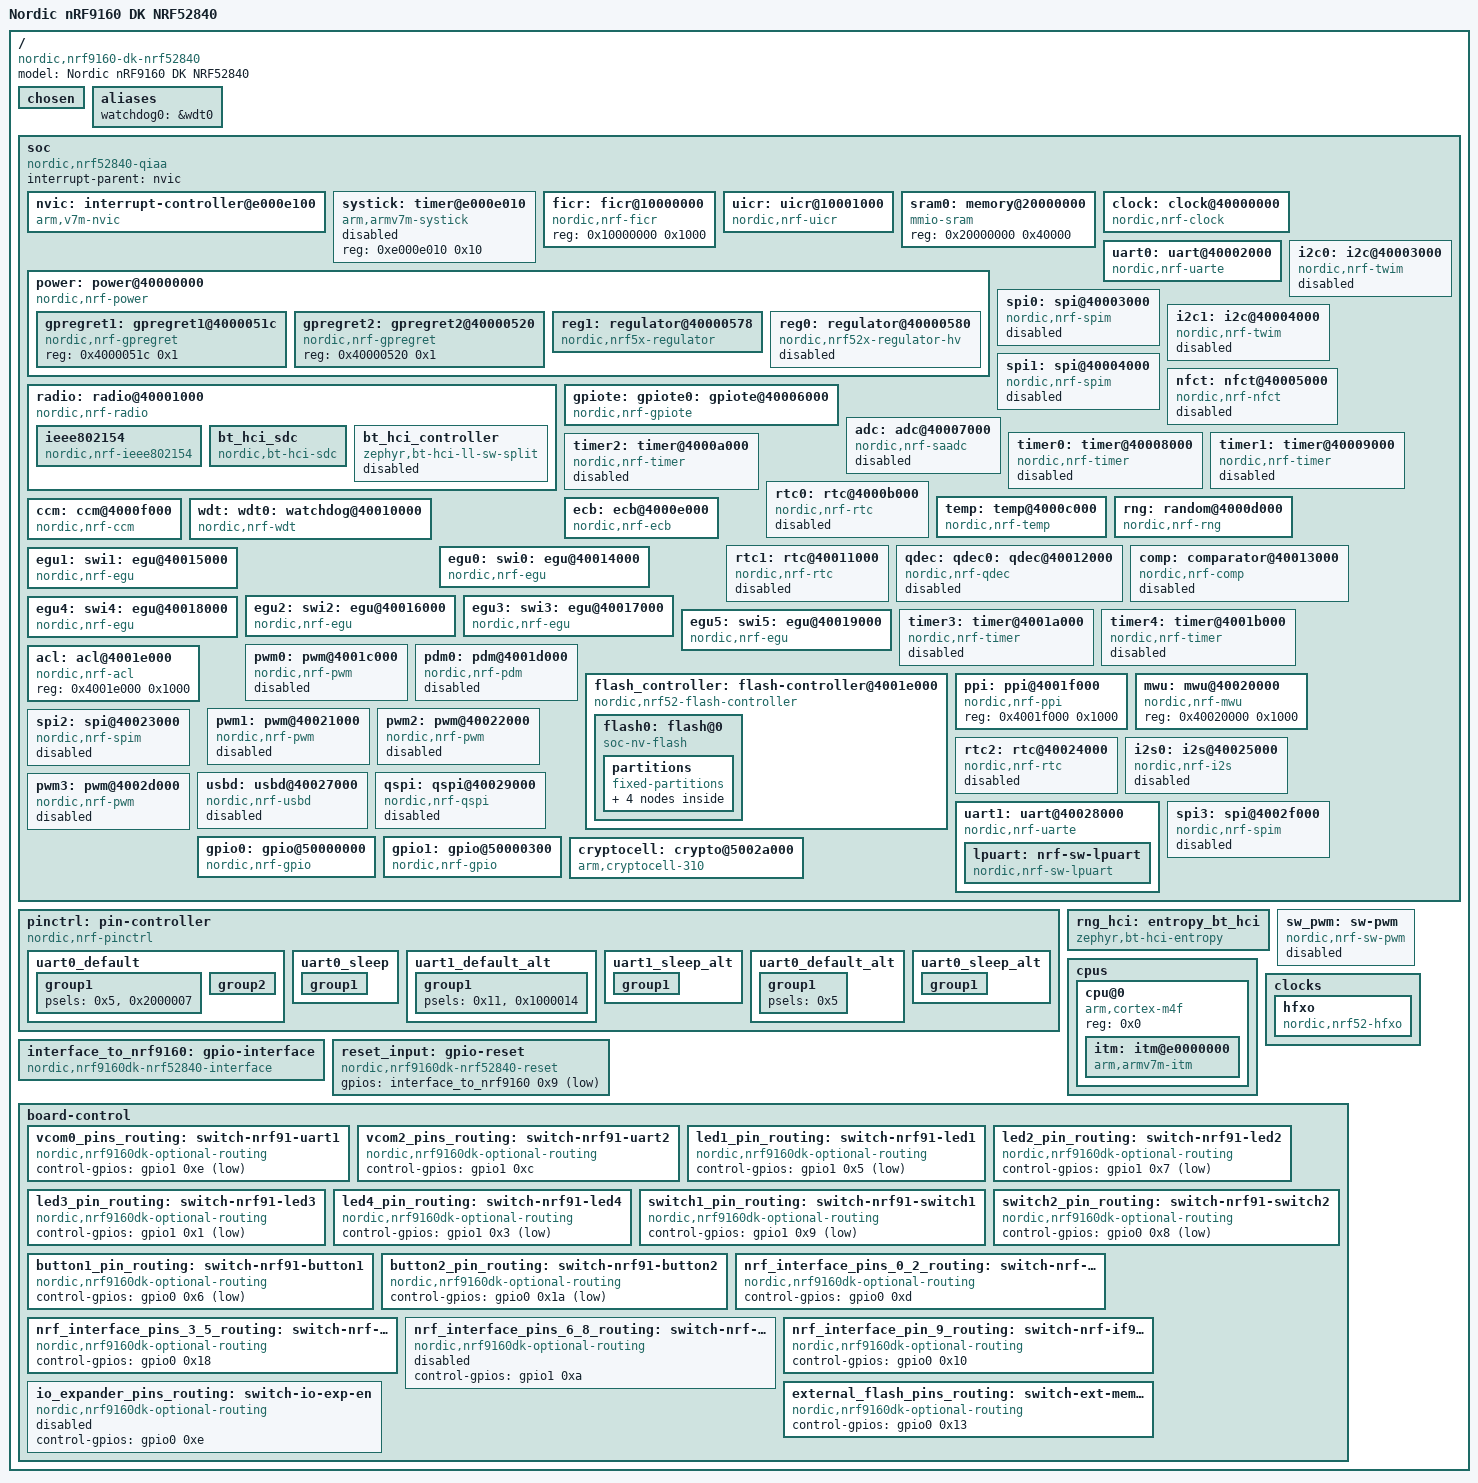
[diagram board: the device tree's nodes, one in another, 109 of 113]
/dts-v1/;

/* node '/' defined in zephyr\dts\common\skeleton.dtsi:9 */
/ {
	#address-cells = < 0x1 >;                  /* in zephyr\dts\common\skeleton.dtsi:10 */
	#size-cells = < 0x1 >;                     /* in zephyr\dts\common\skeleton.dtsi:11 */
	model = "Nordic nRF9160 DK NRF52840";      /* in zephyr\boards\nordic\nrf9160dk\nrf9160dk_nrf52840.dts:14 */
	compatible = "nordic,nrf9160-dk-nrf52840"; /* in zephyr\boards\nordic\nrf9160dk\nrf9160dk_nrf52840.dts:15 */

	/* node '/chosen' defined in zephyr\dts\common\skeleton.dtsi:12 */
	chosen {
		zephyr,bt-hci = &bt_hci_sdc;                 /* in zephyr\dts\arm\nordic\nrf52840.dtsi:10 */
		zephyr,entropy = &cryptocell;                /* in zephyr\dts\arm\nordic\nrf52840.dtsi:11 */
		zephyr,flash-controller = &flash_controller; /* in zephyr\dts\arm\nordic\nrf52840.dtsi:12 */
		zephyr,sram = &sram0;                        /* in zephyr\dts\vendor\nordic\nrf52840_partition.dtsi:9 */
		zephyr,flash = &flash0;                      /* in zephyr\dts\vendor\nordic\nrf52840_partition.dtsi:10 */
		zephyr,code-partition = &slot0_partition;    /* in zephyr\dts\vendor\nordic\nrf52840_partition.dtsi:11 */
		zephyr,console = &uart0;                     /* in zephyr\boards\nordic\nrf9160dk\nrf9160dk_nrf52840.dts:18 */
		zephyr,shell-uart = &uart0;                  /* in zephyr\boards\nordic\nrf9160dk\nrf9160dk_nrf52840.dts:19 */
		zephyr,uart-mcumgr = &uart0;                 /* in zephyr\boards\nordic\nrf9160dk\nrf9160dk_nrf52840.dts:20 */
		zephyr,bt-mon-uart = &uart0;                 /* in zephyr\boards\nordic\nrf9160dk\nrf9160dk_nrf52840.dts:21 */
		zephyr,ieee802154 = &ieee802154;             /* in zephyr\boards\nordic\nrf9160dk\nrf9160dk_nrf52840.dts:22 */
		zephyr,bt-c2h-uart = &lpuart;                /* in pouch-gateway\controller\boards\nrf9160dk_nrf52840.overlay:53 */
	};

	/* node '/aliases' defined in zephyr\dts\common\skeleton.dtsi:13 */
	aliases {
		watchdog0 = &wdt0; /* in zephyr\boards\nordic\nrf9160dk\nrf9160dk_nrf52840.dts:138 */
	};

	/* node '/soc' defined in zephyr\dts\arm\armv7-m.dtsi:6 */
	soc {
		#address-cells = < 0x1 >;            /* in zephyr\dts\arm\armv7-m.dtsi:7 */
		#size-cells = < 0x1 >;               /* in zephyr\dts\arm\armv7-m.dtsi:8 */
		compatible = "nordic,nrf52840-qiaa",
		             "nordic,nrf52840",
		             "nordic,nrf52",
		             "simple-bus";           /* in zephyr\dts\arm\nordic\nrf52840_qiaa.dtsi:29 */
		interrupt-parent = < &nvic >;        /* in zephyr\dts\arm\armv7-m.dtsi:10 */
		ranges;                              /* in zephyr\dts\arm\armv7-m.dtsi:11 */

		/* node '/soc/interrupt-controller@e000e100' defined in zephyr\dts\arm\armv7-m.dtsi:13 */
		nvic: interrupt-controller@e000e100 {
			#address-cells = < 0x1 >;            /* in zephyr\dts\arm\armv7-m.dtsi:14 */
			compatible = "arm,v7m-nvic";         /* in zephyr\dts\arm\armv7-m.dtsi:15 */
			reg = < 0xe000e100 0xc00 >;          /* in zephyr\dts\arm\armv7-m.dtsi:16 */
			interrupt-controller;                /* in zephyr\dts\arm\armv7-m.dtsi:17 */
			#interrupt-cells = < 0x2 >;          /* in zephyr\dts\arm\armv7-m.dtsi:18 */
			arm,num-irq-priority-bits = < 0x3 >; /* in zephyr\dts\arm\nordic\nrf52840.dtsi:582 */
			phandle = < 0x1 >;                   /* in zephyr\dts\arm\armv7-m.dtsi:10 */
		};

		/* node '/soc/timer@e000e010' defined in zephyr\dts\arm\armv7-m.dtsi:21 */
		systick: timer@e000e010 {
			compatible = "arm,armv7m-systick"; /* in zephyr\dts\arm\armv7-m.dtsi:22 */
			reg = < 0xe000e010 0x10 >;         /* in zephyr\dts\arm\armv7-m.dtsi:23 */
			status = "disabled";               /* in zephyr\dts\arm\nordic\nrf52840.dtsi:587 */
		};

		/* node '/soc/ficr@10000000' defined in zephyr\dts\arm\nordic\nrf52840.dtsi:44 */
		ficr: ficr@10000000 {
			compatible = "nordic,nrf-ficr"; /* in zephyr\dts\arm\nordic\nrf52840.dtsi:45 */
			reg = < 0x10000000 0x1000 >;    /* in zephyr\dts\arm\nordic\nrf52840.dtsi:46 */
			#nordic,ficr-cells = < 0x1 >;   /* in zephyr\dts\arm\nordic\nrf52840.dtsi:47 */
			status = "okay";                /* in zephyr\dts\arm\nordic\nrf52840.dtsi:48 */
		};

		/* node '/soc/uicr@10001000' defined in zephyr\dts\arm\nordic\nrf52840.dtsi:51 */
		uicr: uicr@10001000 {
			compatible = "nordic,nrf-uicr"; /* in zephyr\dts\arm\nordic\nrf52840.dtsi:52 */
			reg = < 0x10001000 0x1000 >;    /* in zephyr\dts\arm\nordic\nrf52840.dtsi:53 */
			status = "okay";                /* in zephyr\dts\arm\nordic\nrf52840.dtsi:54 */
			gpio-as-nreset;                 /* in zephyr\boards\nordic\nrf9160dk\nrf9160dk_nrf52840.dts:147 */
		};

		/* node '/soc/memory@20000000' defined in zephyr\dts\arm\nordic\nrf52840.dtsi:57 */
		sram0: memory@20000000 {
			compatible = "mmio-sram";     /* in zephyr\dts\arm\nordic\nrf52840.dtsi:58 */
			reg = < 0x20000000 0x40000 >; /* in zephyr\dts\arm\nordic\nrf52840_qiaa.dtsi:15 */
		};

		/* node '/soc/clock@40000000' defined in zephyr\dts\arm\nordic\nrf52840.dtsi:61 */
		clock: clock@40000000 {
			compatible = "nordic,nrf-clock"; /* in zephyr\dts\arm\nordic\nrf52840.dtsi:62 */
			reg = < 0x40000000 0x1000 >;     /* in zephyr\dts\arm\nordic\nrf52840.dtsi:63 */
			interrupts = < 0x0 0x1 >;        /* in zephyr\dts\arm\nordic\nrf52840.dtsi:64 */
			status = "okay";                 /* in zephyr\dts\arm\nordic\nrf52840.dtsi:65 */
		};

		/* node '/soc/power@40000000' defined in zephyr\dts\arm\nordic\nrf52840.dtsi:68 */
		power: power@40000000 {
			compatible = "nordic,nrf-power"; /* in zephyr\dts\arm\nordic\nrf52840.dtsi:69 */
			reg = < 0x40000000 0x1000 >;     /* in zephyr\dts\arm\nordic\nrf52840.dtsi:70 */
			interrupts = < 0x0 0x1 >;        /* in zephyr\dts\arm\nordic\nrf52840.dtsi:71 */
			status = "okay";                 /* in zephyr\dts\arm\nordic\nrf52840.dtsi:72 */
			#address-cells = < 0x1 >;        /* in zephyr\dts\arm\nordic\nrf52840.dtsi:73 */
			#size-cells = < 0x1 >;           /* in zephyr\dts\arm\nordic\nrf52840.dtsi:74 */

			/* node '/soc/power@40000000/gpregret1@4000051c' defined in zephyr\dts\arm\nordic\nrf52840.dtsi:76 */
			gpregret1: gpregret1@4000051c {
				#address-cells = < 0x1 >;           /* in zephyr\dts\arm\nordic\nrf52840.dtsi:77 */
				#size-cells = < 0x1 >;              /* in zephyr\dts\arm\nordic\nrf52840.dtsi:78 */
				compatible = "nordic,nrf-gpregret"; /* in zephyr\dts\arm\nordic\nrf52840.dtsi:79 */
				reg = < 0x4000051c 0x1 >;           /* in zephyr\dts\arm\nordic\nrf52840.dtsi:80 */
				status = "okay";                    /* in zephyr\dts\arm\nordic\nrf52840.dtsi:81 */
			};

			/* node '/soc/power@40000000/gpregret2@40000520' defined in zephyr\dts\arm\nordic\nrf52840.dtsi:84 */
			gpregret2: gpregret2@40000520 {
				#address-cells = < 0x1 >;           /* in zephyr\dts\arm\nordic\nrf52840.dtsi:85 */
				#size-cells = < 0x1 >;              /* in zephyr\dts\arm\nordic\nrf52840.dtsi:86 */
				compatible = "nordic,nrf-gpregret"; /* in zephyr\dts\arm\nordic\nrf52840.dtsi:87 */
				reg = < 0x40000520 0x1 >;           /* in zephyr\dts\arm\nordic\nrf52840.dtsi:88 */
				status = "okay";                    /* in zephyr\dts\arm\nordic\nrf52840.dtsi:89 */
			};

			/* node '/soc/power@40000000/regulator@40000578' defined in zephyr\dts\arm\nordic\nrf52840.dtsi:92 */
			reg1: regulator@40000578 {
				compatible = "nordic,nrf5x-regulator"; /* in zephyr\dts\arm\nordic\nrf52840.dtsi:93 */
				reg = < 0x40000578 0x1 >;              /* in zephyr\dts\arm\nordic\nrf52840.dtsi:94 */
				regulator-name = "REG1";               /* in zephyr\dts\arm\nordic\nrf52840.dtsi:95 */
				regulator-initial-mode = < 0x1 >;      /* in zephyr\boards\nordic\nrf9160dk\nrf9160dk_nrf52840.dts:143 */
			};

			/* node '/soc/power@40000000/regulator@40000580' defined in zephyr\dts\arm\nordic\nrf52840_qiaa.dtsi:19 */
			reg0: regulator@40000580 {
				compatible = "nordic,nrf52x-regulator-hv"; /* in zephyr\dts\arm\nordic\nrf52840_qiaa.dtsi:20 */
				reg = < 0x40000580 0x1 >;                  /* in zephyr\dts\arm\nordic\nrf52840_qiaa.dtsi:21 */
				regulator-name = "REG0";                   /* in zephyr\dts\arm\nordic\nrf52840_qiaa.dtsi:22 */
				status = "disabled";                       /* in zephyr\dts\arm\nordic\nrf52840_qiaa.dtsi:23 */
			};
		};

		/* node '/soc/radio@40001000' defined in zephyr\dts\arm\nordic\nrf52840.dtsi:100 */
		radio: radio@40001000 {
			compatible = "nordic,nrf-radio"; /* in zephyr\dts\arm\nordic\nrf52840.dtsi:101 */
			reg = < 0x40001000 0x1000 >;     /* in zephyr\dts\arm\nordic\nrf52840.dtsi:102 */
			interrupts = < 0x1 0x1 >;        /* in zephyr\dts\arm\nordic\nrf52840.dtsi:103 */
			status = "okay";                 /* in zephyr\dts\arm\nordic\nrf52840.dtsi:104 */
			ieee802154-supported;            /* in zephyr\dts\arm\nordic\nrf52840.dtsi:105 */
			ble-2mbps-supported;             /* in zephyr\dts\arm\nordic\nrf52840.dtsi:106 */
			ble-coded-phy-supported;         /* in zephyr\dts\arm\nordic\nrf52840.dtsi:107 */
			tx-high-power-supported;         /* in zephyr\dts\arm\nordic\nrf52840.dtsi:108 */

			/* node '/soc/radio@40001000/ieee802154' defined in zephyr\dts\arm\nordic\nrf52840.dtsi:110 */
			ieee802154: ieee802154 {
				compatible = "nordic,nrf-ieee802154"; /* in zephyr\dts\arm\nordic\nrf52840.dtsi:111 */
				status = "okay";                      /* in zephyr\boards\nordic\nrf9160dk\nrf9160dk_nrf52840.dts:176 */
			};

			/* node '/soc/radio@40001000/bt_hci_sdc' defined in zephyr\dts\arm\nordic\nrf52840.dtsi:115 */
			bt_hci_sdc: bt_hci_sdc {
				compatible = "nordic,bt-hci-sdc"; /* in zephyr\dts\arm\nordic\nrf52840.dtsi:116 */
				status = "okay";                  /* in zephyr\dts\arm\nordic\nrf52840.dtsi:117 */
			};

			/* node '/soc/radio@40001000/bt_hci_controller' defined in zephyr\dts\arm\nordic\nrf52840.dtsi:119 */
			bt_hci_controller: bt_hci_controller {
				compatible = "zephyr,bt-hci-ll-sw-split"; /* in zephyr\dts\arm\nordic\nrf52840.dtsi:120 */
				status = "disabled";                      /* in zephyr\dts\arm\nordic\nrf52840.dtsi:121 */
			};
		};

		/* node '/soc/uart@40002000' defined in zephyr\dts\arm\nordic\nrf52840.dtsi:125 */
		uart0: uart@40002000 {
			compatible = "nordic,nrf-uarte";    /* in zephyr\boards\nordic\nrf9160dk\nrf9160dk_nrf52840.dts:167 */
			reg = < 0x40002000 0x1000 >;        /* in zephyr\dts\arm\nordic\nrf52840.dtsi:129 */
			interrupts = < 0x2 0x1 >;           /* in zephyr\dts\arm\nordic\nrf52840.dtsi:130 */
			status = "okay";                    /* in zephyr\boards\nordic\nrf9160dk\nrf9160dk_nrf52840.dts:169 */
			current-speed = < 0x1c200 >;        /* in zephyr\boards\nordic\nrf9160dk\nrf9160dk_nrf52840.dts:168 */
			pinctrl-0 = < &uart0_default_alt >; /* in pouch-gateway\controller\boards\nrf9160dk_nrf52840.overlay:63 */
			pinctrl-1 = < &uart0_sleep_alt >;   /* in pouch-gateway\controller\boards\nrf9160dk_nrf52840.overlay:64 */
			pinctrl-names = "default",
			                "sleep";            /* in pouch-gateway\controller\boards\nrf9160dk_nrf52840.overlay:65 */
			disable-rx;                         /* in pouch-gateway\controller\boards\nrf9160dk_nrf52840.overlay:66 */
		};

		/* node '/soc/i2c@40003000' defined in zephyr\dts\arm\nordic\nrf52840.dtsi:134 */
		i2c0: i2c@40003000 {
			compatible = "nordic,nrf-twim"; /* in zephyr\dts\arm\nordic\nrf52840.dtsi:142 */
			#address-cells = < 0x1 >;       /* in zephyr\dts\arm\nordic\nrf52840.dtsi:143 */
			#size-cells = < 0x0 >;          /* in zephyr\dts\arm\nordic\nrf52840.dtsi:144 */
			reg = < 0x40003000 0x1000 >;    /* in zephyr\dts\arm\nordic\nrf52840.dtsi:145 */
			interrupts = < 0x3 0x1 >;       /* in zephyr\dts\arm\nordic\nrf52840.dtsi:146 */
			easydma-maxcnt-bits = < 0x10 >; /* in zephyr\dts\arm\nordic\nrf52840.dtsi:147 */
			status = "disabled";            /* in zephyr\dts\arm\nordic\nrf52840.dtsi:148 */
			zephyr,pm-device-runtime-auto;  /* in zephyr\dts\arm\nordic\nrf52840.dtsi:149 */
		};

		/* node '/soc/spi@40003000' defined in zephyr\dts\arm\nordic\nrf52840.dtsi:152 */
		spi0: spi@40003000 {
			compatible = "nordic,nrf-spim"; /* in zephyr\dts\arm\nordic\nrf52840.dtsi:160 */
			#address-cells = < 0x1 >;       /* in zephyr\dts\arm\nordic\nrf52840.dtsi:161 */
			#size-cells = < 0x0 >;          /* in zephyr\dts\arm\nordic\nrf52840.dtsi:162 */
			reg = < 0x40003000 0x1000 >;    /* in zephyr\dts\arm\nordic\nrf52840.dtsi:163 */
			interrupts = < 0x3 0x1 >;       /* in zephyr\dts\arm\nordic\nrf52840.dtsi:164 */
			max-frequency = < 0x7a1200 >;   /* in zephyr\dts\arm\nordic\nrf52840.dtsi:165 */
			easydma-maxcnt-bits = < 0x10 >; /* in zephyr\dts\arm\nordic\nrf52840.dtsi:166 */
			status = "disabled";            /* in zephyr\dts\arm\nordic\nrf52840.dtsi:167 */
		};

		/* node '/soc/i2c@40004000' defined in zephyr\dts\arm\nordic\nrf52840.dtsi:170 */
		i2c1: i2c@40004000 {
			compatible = "nordic,nrf-twim"; /* in zephyr\dts\arm\nordic\nrf52840.dtsi:178 */
			#address-cells = < 0x1 >;       /* in zephyr\dts\arm\nordic\nrf52840.dtsi:179 */
			#size-cells = < 0x0 >;          /* in zephyr\dts\arm\nordic\nrf52840.dtsi:180 */
			reg = < 0x40004000 0x1000 >;    /* in zephyr\dts\arm\nordic\nrf52840.dtsi:181 */
			interrupts = < 0x4 0x1 >;       /* in zephyr\dts\arm\nordic\nrf52840.dtsi:182 */
			easydma-maxcnt-bits = < 0x10 >; /* in zephyr\dts\arm\nordic\nrf52840.dtsi:183 */
			status = "disabled";            /* in zephyr\dts\arm\nordic\nrf52840.dtsi:184 */
			zephyr,pm-device-runtime-auto;  /* in zephyr\dts\arm\nordic\nrf52840.dtsi:185 */
		};

		/* node '/soc/spi@40004000' defined in zephyr\dts\arm\nordic\nrf52840.dtsi:188 */
		spi1: spi@40004000 {
			compatible = "nordic,nrf-spim"; /* in zephyr\dts\arm\nordic\nrf52840.dtsi:196 */
			#address-cells = < 0x1 >;       /* in zephyr\dts\arm\nordic\nrf52840.dtsi:197 */
			#size-cells = < 0x0 >;          /* in zephyr\dts\arm\nordic\nrf52840.dtsi:198 */
			reg = < 0x40004000 0x1000 >;    /* in zephyr\dts\arm\nordic\nrf52840.dtsi:199 */
			interrupts = < 0x4 0x1 >;       /* in zephyr\dts\arm\nordic\nrf52840.dtsi:200 */
			max-frequency = < 0x7a1200 >;   /* in zephyr\dts\arm\nordic\nrf52840.dtsi:201 */
			easydma-maxcnt-bits = < 0x10 >; /* in zephyr\dts\arm\nordic\nrf52840.dtsi:202 */
			status = "disabled";            /* in zephyr\dts\arm\nordic\nrf52840.dtsi:203 */
		};

		/* node '/soc/nfct@40005000' defined in zephyr\dts\arm\nordic\nrf52840.dtsi:206 */
		nfct: nfct@40005000 {
			compatible = "nordic,nrf-nfct"; /* in zephyr\dts\arm\nordic\nrf52840.dtsi:207 */
			reg = < 0x40005000 0x1000 >;    /* in zephyr\dts\arm\nordic\nrf52840.dtsi:208 */
			interrupts = < 0x5 0x1 >;       /* in zephyr\dts\arm\nordic\nrf52840.dtsi:209 */
			status = "disabled";            /* in zephyr\dts\arm\nordic\nrf52840.dtsi:210 */
		};

		/* node '/soc/gpiote@40006000' defined in zephyr\dts\arm\nordic\nrf52840.dtsi:213 */
		gpiote: gpiote0: gpiote@40006000 {
			compatible = "nordic,nrf-gpiote"; /* in zephyr\dts\arm\nordic\nrf52840.dtsi:214 */
			reg = < 0x40006000 0x1000 >;      /* in zephyr\dts\arm\nordic\nrf52840.dtsi:215 */
			interrupts = < 0x6 0x1 >;         /* in pouch-gateway\controller\boards\nrf9160dk_nrf52840.overlay:58 */
			status = "okay";                  /* in zephyr\boards\nordic\nrf9160dk\nrf9160dk_nrf52840.dts:151 */
			instance = < 0x0 >;               /* in zephyr\dts\arm\nordic\nrf52840.dtsi:218 */
			phandle = < 0x6 >;                /* in zephyr\dts\arm\nordic\nrf52840.dtsi:556 */
		};

		/* node '/soc/adc@40007000' defined in zephyr\dts\arm\nordic\nrf52840.dtsi:221 */
		adc: adc@40007000 {
			compatible = "nordic,nrf-saadc"; /* in zephyr\dts\arm\nordic\nrf52840.dtsi:222 */
			reg = < 0x40007000 0x1000 >;     /* in zephyr\dts\arm\nordic\nrf52840.dtsi:223 */
			interrupts = < 0x7 0x1 >;        /* in zephyr\dts\arm\nordic\nrf52840.dtsi:224 */
			status = "disabled";             /* in zephyr\dts\arm\nordic\nrf52840.dtsi:225 */
			#io-channel-cells = < 0x1 >;     /* in zephyr\dts\arm\nordic\nrf52840.dtsi:226 */
			zephyr,pm-device-runtime-auto;   /* in zephyr\dts\arm\nordic\nrf52840.dtsi:227 */
		};

		/* node '/soc/timer@40008000' defined in zephyr\dts\arm\nordic\nrf52840.dtsi:230 */
		timer0: timer@40008000 {
			compatible = "nordic,nrf-timer"; /* in zephyr\dts\arm\nordic\nrf52840.dtsi:231 */
			status = "disabled";             /* in zephyr\dts\arm\nordic\nrf52840.dtsi:232 */
			reg = < 0x40008000 0x1000 >;     /* in zephyr\dts\arm\nordic\nrf52840.dtsi:233 */
			cc-num = < 0x4 >;                /* in zephyr\dts\arm\nordic\nrf52840.dtsi:234 */
			max-bit-width = < 0x20 >;        /* in zephyr\dts\arm\nordic\nrf52840.dtsi:235 */
			interrupts = < 0x8 0x1 >;        /* in zephyr\dts\arm\nordic\nrf52840.dtsi:236 */
			prescaler = < 0x0 >;             /* in zephyr\dts\arm\nordic\nrf52840.dtsi:237 */
		};

		/* node '/soc/timer@40009000' defined in zephyr\dts\arm\nordic\nrf52840.dtsi:240 */
		timer1: timer@40009000 {
			compatible = "nordic,nrf-timer"; /* in zephyr\dts\arm\nordic\nrf52840.dtsi:241 */
			status = "disabled";             /* in zephyr\dts\arm\nordic\nrf52840.dtsi:242 */
			reg = < 0x40009000 0x1000 >;     /* in zephyr\dts\arm\nordic\nrf52840.dtsi:243 */
			cc-num = < 0x4 >;                /* in zephyr\dts\arm\nordic\nrf52840.dtsi:244 */
			max-bit-width = < 0x20 >;        /* in zephyr\dts\arm\nordic\nrf52840.dtsi:245 */
			interrupts = < 0x9 0x1 >;        /* in zephyr\dts\arm\nordic\nrf52840.dtsi:246 */
			prescaler = < 0x0 >;             /* in zephyr\dts\arm\nordic\nrf52840.dtsi:247 */
			phandle = < 0x7 >;               /* in zephyr\dts\vendor\nordic\nrf_common.dtsi:41 */
		};

		/* node '/soc/timer@4000a000' defined in zephyr\dts\arm\nordic\nrf52840.dtsi:250 */
		timer2: timer@4000a000 {
			compatible = "nordic,nrf-timer"; /* in zephyr\dts\arm\nordic\nrf52840.dtsi:251 */
			status = "disabled";             /* in zephyr\dts\arm\nordic\nrf52840.dtsi:252 */
			reg = < 0x4000a000 0x1000 >;     /* in zephyr\dts\arm\nordic\nrf52840.dtsi:253 */
			cc-num = < 0x4 >;                /* in zephyr\dts\arm\nordic\nrf52840.dtsi:254 */
			max-bit-width = < 0x20 >;        /* in zephyr\dts\arm\nordic\nrf52840.dtsi:255 */
			interrupts = < 0xa 0x1 >;        /* in zephyr\dts\arm\nordic\nrf52840.dtsi:256 */
			prescaler = < 0x0 >;             /* in zephyr\dts\arm\nordic\nrf52840.dtsi:257 */
		};

		/* node '/soc/rtc@4000b000' defined in zephyr\dts\arm\nordic\nrf52840.dtsi:260 */
		rtc0: rtc@4000b000 {
			compatible = "nordic,nrf-rtc"; /* in zephyr\dts\arm\nordic\nrf52840.dtsi:261 */
			reg = < 0x4000b000 0x1000 >;   /* in zephyr\dts\arm\nordic\nrf52840.dtsi:262 */
			cc-num = < 0x3 >;              /* in zephyr\dts\arm\nordic\nrf52840.dtsi:263 */
			interrupts = < 0xb 0x1 >;      /* in zephyr\dts\arm\nordic\nrf52840.dtsi:264 */
			status = "disabled";           /* in zephyr\dts\arm\nordic\nrf52840.dtsi:265 */
			clock-frequency = < 0x8000 >;  /* in zephyr\dts\arm\nordic\nrf52840.dtsi:266 */
			prescaler = < 0x1 >;           /* in zephyr\dts\arm\nordic\nrf52840.dtsi:267 */
		};

		/* node '/soc/temp@4000c000' defined in zephyr\dts\arm\nordic\nrf52840.dtsi:270 */
		temp: temp@4000c000 {
			compatible = "nordic,nrf-temp"; /* in zephyr\dts\arm\nordic\nrf52840.dtsi:271 */
			reg = < 0x4000c000 0x1000 >;    /* in zephyr\dts\arm\nordic\nrf52840.dtsi:272 */
			interrupts = < 0xc 0x1 >;       /* in zephyr\dts\arm\nordic\nrf52840.dtsi:273 */
			status = "okay";                /* in zephyr\dts\arm\nordic\nrf52840.dtsi:274 */
		};

		/* node '/soc/random@4000d000' defined in zephyr\dts\arm\nordic\nrf52840.dtsi:277 */
		rng: random@4000d000 {
			compatible = "nordic,nrf-rng"; /* in zephyr\dts\arm\nordic\nrf52840.dtsi:278 */
			reg = < 0x4000d000 0x1000 >;   /* in zephyr\dts\arm\nordic\nrf52840.dtsi:279 */
			interrupts = < 0xd 0x1 >;      /* in zephyr\dts\arm\nordic\nrf52840.dtsi:280 */
			status = "okay";               /* in zephyr\dts\arm\nordic\nrf52840.dtsi:281 */
		};

		/* node '/soc/ecb@4000e000' defined in zephyr\dts\arm\nordic\nrf52840.dtsi:284 */
		ecb: ecb@4000e000 {
			compatible = "nordic,nrf-ecb"; /* in zephyr\dts\arm\nordic\nrf52840.dtsi:285 */
			reg = < 0x4000e000 0x1000 >;   /* in zephyr\dts\arm\nordic\nrf52840.dtsi:286 */
			interrupts = < 0xe 0x1 >;      /* in zephyr\dts\arm\nordic\nrf52840.dtsi:287 */
			status = "okay";               /* in zephyr\dts\arm\nordic\nrf52840.dtsi:288 */
		};

		/* node '/soc/ccm@4000f000' defined in zephyr\dts\arm\nordic\nrf52840.dtsi:291 */
		ccm: ccm@4000f000 {
			compatible = "nordic,nrf-ccm"; /* in zephyr\dts\arm\nordic\nrf52840.dtsi:292 */
			reg = < 0x4000f000 0x1000 >;   /* in zephyr\dts\arm\nordic\nrf52840.dtsi:293 */
			interrupts = < 0xf 0x1 >;      /* in zephyr\dts\arm\nordic\nrf52840.dtsi:294 */
			length-field-length-8-bits;    /* in zephyr\dts\arm\nordic\nrf52840.dtsi:295 */
			status = "okay";               /* in zephyr\dts\arm\nordic\nrf52840.dtsi:296 */
		};

		/* node '/soc/watchdog@40010000' defined in zephyr\dts\arm\nordic\nrf52840.dtsi:299 */
		wdt: wdt0: watchdog@40010000 {
			compatible = "nordic,nrf-wdt"; /* in zephyr\dts\arm\nordic\nrf52840.dtsi:300 */
			reg = < 0x40010000 0x1000 >;   /* in zephyr\dts\arm\nordic\nrf52840.dtsi:301 */
			interrupts = < 0x10 0x1 >;     /* in zephyr\dts\arm\nordic\nrf52840.dtsi:302 */
			status = "okay";               /* in zephyr\dts\arm\nordic\nrf52840.dtsi:303 */
		};

		/* node '/soc/rtc@40011000' defined in zephyr\dts\arm\nordic\nrf52840.dtsi:306 */
		rtc1: rtc@40011000 {
			compatible = "nordic,nrf-rtc"; /* in zephyr\dts\arm\nordic\nrf52840.dtsi:307 */
			reg = < 0x40011000 0x1000 >;   /* in zephyr\dts\arm\nordic\nrf52840.dtsi:308 */
			cc-num = < 0x4 >;              /* in zephyr\dts\arm\nordic\nrf52840.dtsi:309 */
			interrupts = < 0x11 0x1 >;     /* in zephyr\dts\arm\nordic\nrf52840.dtsi:310 */
			status = "disabled";           /* in zephyr\dts\arm\nordic\nrf52840.dtsi:311 */
			clock-frequency = < 0x8000 >;  /* in zephyr\dts\arm\nordic\nrf52840.dtsi:312 */
			prescaler = < 0x1 >;           /* in zephyr\dts\arm\nordic\nrf52840.dtsi:313 */
		};

		/* node '/soc/qdec@40012000' defined in zephyr\dts\arm\nordic\nrf52840.dtsi:316 */
		qdec: qdec0: qdec@40012000 {
			compatible = "nordic,nrf-qdec"; /* in zephyr\dts\arm\nordic\nrf52840.dtsi:317 */
			reg = < 0x40012000 0x1000 >;    /* in zephyr\dts\arm\nordic\nrf52840.dtsi:318 */
			interrupts = < 0x12 0x1 >;      /* in zephyr\dts\arm\nordic\nrf52840.dtsi:319 */
			status = "disabled";            /* in zephyr\dts\arm\nordic\nrf52840.dtsi:320 */
		};

		/* node '/soc/comparator@40013000' defined in zephyr\dts\arm\nordic\nrf52840.dtsi:323 */
		comp: comparator@40013000 {
			compatible = "nordic,nrf-comp"; /* in zephyr\dts\arm\nordic\nrf52840.dtsi:328 */
			reg = < 0x40013000 0x1000 >;    /* in zephyr\dts\arm\nordic\nrf52840.dtsi:329 */
			interrupts = < 0x13 0x1 >;      /* in zephyr\dts\arm\nordic\nrf52840.dtsi:330 */
			status = "disabled";            /* in zephyr\dts\arm\nordic\nrf52840.dtsi:331 */
		};

		/* node '/soc/egu@40014000' defined in zephyr\dts\arm\nordic\nrf52840.dtsi:334 */
		egu0: swi0: egu@40014000 {
			compatible = "nordic,nrf-egu",
			             "nordic,nrf-swi"; /* in zephyr\dts\arm\nordic\nrf52840.dtsi:335 */
			reg = < 0x40014000 0x1000 >;   /* in zephyr\dts\arm\nordic\nrf52840.dtsi:336 */
			interrupts = < 0x14 0x1 >;     /* in zephyr\dts\arm\nordic\nrf52840.dtsi:337 */
			status = "okay";               /* in zephyr\dts\arm\nordic\nrf52840.dtsi:338 */
		};

		/* node '/soc/egu@40015000' defined in zephyr\dts\arm\nordic\nrf52840.dtsi:341 */
		egu1: swi1: egu@40015000 {
			compatible = "nordic,nrf-egu",
			             "nordic,nrf-swi"; /* in zephyr\dts\arm\nordic\nrf52840.dtsi:342 */
			reg = < 0x40015000 0x1000 >;   /* in zephyr\dts\arm\nordic\nrf52840.dtsi:343 */
			interrupts = < 0x15 0x1 >;     /* in zephyr\dts\arm\nordic\nrf52840.dtsi:344 */
			status = "okay";               /* in zephyr\dts\arm\nordic\nrf52840.dtsi:345 */
		};

		/* node '/soc/egu@40016000' defined in zephyr\dts\arm\nordic\nrf52840.dtsi:348 */
		egu2: swi2: egu@40016000 {
			compatible = "nordic,nrf-egu",
			             "nordic,nrf-swi"; /* in zephyr\dts\arm\nordic\nrf52840.dtsi:349 */
			reg = < 0x40016000 0x1000 >;   /* in zephyr\dts\arm\nordic\nrf52840.dtsi:350 */
			interrupts = < 0x16 0x1 >;     /* in zephyr\dts\arm\nordic\nrf52840.dtsi:351 */
			status = "okay";               /* in zephyr\dts\arm\nordic\nrf52840.dtsi:352 */
		};

		/* node '/soc/egu@40017000' defined in zephyr\dts\arm\nordic\nrf52840.dtsi:355 */
		egu3: swi3: egu@40017000 {
			compatible = "nordic,nrf-egu",
			             "nordic,nrf-swi"; /* in zephyr\dts\arm\nordic\nrf52840.dtsi:356 */
			reg = < 0x40017000 0x1000 >;   /* in zephyr\dts\arm\nordic\nrf52840.dtsi:357 */
			interrupts = < 0x17 0x1 >;     /* in zephyr\dts\arm\nordic\nrf52840.dtsi:358 */
			status = "okay";               /* in zephyr\dts\arm\nordic\nrf52840.dtsi:359 */
		};

		/* node '/soc/egu@40018000' defined in zephyr\dts\arm\nordic\nrf52840.dtsi:362 */
		egu4: swi4: egu@40018000 {
			compatible = "nordic,nrf-egu",
			             "nordic,nrf-swi"; /* in zephyr\dts\arm\nordic\nrf52840.dtsi:363 */
			reg = < 0x40018000 0x1000 >;   /* in zephyr\dts\arm\nordic\nrf52840.dtsi:364 */
			interrupts = < 0x18 0x1 >;     /* in zephyr\dts\arm\nordic\nrf52840.dtsi:365 */
			status = "okay";               /* in zephyr\dts\arm\nordic\nrf52840.dtsi:366 */
		};

		/* node '/soc/egu@40019000' defined in zephyr\dts\arm\nordic\nrf52840.dtsi:369 */
		egu5: swi5: egu@40019000 {
			compatible = "nordic,nrf-egu",
			             "nordic,nrf-swi"; /* in zephyr\dts\arm\nordic\nrf52840.dtsi:370 */
			reg = < 0x40019000 0x1000 >;   /* in zephyr\dts\arm\nordic\nrf52840.dtsi:371 */
			interrupts = < 0x19 0x1 >;     /* in zephyr\dts\arm\nordic\nrf52840.dtsi:372 */
			status = "okay";               /* in zephyr\dts\arm\nordic\nrf52840.dtsi:373 */
		};

		/* node '/soc/timer@4001a000' defined in zephyr\dts\arm\nordic\nrf52840.dtsi:376 */
		timer3: timer@4001a000 {
			compatible = "nordic,nrf-timer"; /* in zephyr\dts\arm\nordic\nrf52840.dtsi:377 */
			status = "disabled";             /* in zephyr\dts\arm\nordic\nrf52840.dtsi:378 */
			reg = < 0x4001a000 0x1000 >;     /* in zephyr\dts\arm\nordic\nrf52840.dtsi:379 */
			cc-num = < 0x6 >;                /* in zephyr\dts\arm\nordic\nrf52840.dtsi:380 */
			max-bit-width = < 0x20 >;        /* in zephyr\dts\arm\nordic\nrf52840.dtsi:381 */
			interrupts = < 0x1a 0x1 >;       /* in zephyr\dts\arm\nordic\nrf52840.dtsi:382 */
			prescaler = < 0x0 >;             /* in zephyr\dts\arm\nordic\nrf52840.dtsi:383 */
		};

		/* node '/soc/timer@4001b000' defined in zephyr\dts\arm\nordic\nrf52840.dtsi:386 */
		timer4: timer@4001b000 {
			compatible = "nordic,nrf-timer"; /* in zephyr\dts\arm\nordic\nrf52840.dtsi:387 */
			status = "disabled";             /* in zephyr\dts\arm\nordic\nrf52840.dtsi:388 */
			reg = < 0x4001b000 0x1000 >;     /* in zephyr\dts\arm\nordic\nrf52840.dtsi:389 */
			cc-num = < 0x6 >;                /* in zephyr\dts\arm\nordic\nrf52840.dtsi:390 */
			max-bit-width = < 0x20 >;        /* in zephyr\dts\arm\nordic\nrf52840.dtsi:391 */
			interrupts = < 0x1b 0x1 >;       /* in zephyr\dts\arm\nordic\nrf52840.dtsi:392 */
			prescaler = < 0x0 >;             /* in zephyr\dts\arm\nordic\nrf52840.dtsi:393 */
		};

		/* node '/soc/pwm@4001c000' defined in zephyr\dts\arm\nordic\nrf52840.dtsi:396 */
		pwm0: pwm@4001c000 {
			compatible = "nordic,nrf-pwm"; /* in zephyr\dts\arm\nordic\nrf52840.dtsi:397 */
			reg = < 0x4001c000 0x1000 >;   /* in zephyr\dts\arm\nordic\nrf52840.dtsi:398 */
			interrupts = < 0x1c 0x1 >;     /* in zephyr\dts\arm\nordic\nrf52840.dtsi:399 */
			status = "disabled";           /* in zephyr\dts\arm\nordic\nrf52840.dtsi:400 */
			#pwm-cells = < 0x3 >;          /* in zephyr\dts\arm\nordic\nrf52840.dtsi:401 */
		};

		/* node '/soc/pdm@4001d000' defined in zephyr\dts\arm\nordic\nrf52840.dtsi:404 */
		pdm0: pdm@4001d000 {
			compatible = "nordic,nrf-pdm"; /* in zephyr\dts\arm\nordic\nrf52840.dtsi:405 */
			reg = < 0x4001d000 0x1000 >;   /* in zephyr\dts\arm\nordic\nrf52840.dtsi:406 */
			interrupts = < 0x1d 0x1 >;     /* in zephyr\dts\arm\nordic\nrf52840.dtsi:407 */
			status = "disabled";           /* in zephyr\dts\arm\nordic\nrf52840.dtsi:408 */
		};

		/* node '/soc/acl@4001e000' defined in zephyr\dts\arm\nordic\nrf52840.dtsi:411 */
		acl: acl@4001e000 {
			compatible = "nordic,nrf-acl"; /* in zephyr\dts\arm\nordic\nrf52840.dtsi:412 */
			reg = < 0x4001e000 0x1000 >;   /* in zephyr\dts\arm\nordic\nrf52840.dtsi:413 */
			status = "okay";               /* in zephyr\dts\arm\nordic\nrf52840.dtsi:414 */
		};

		/* node '/soc/flash-controller@4001e000' defined in zephyr\dts\arm\nordic\nrf52840.dtsi:417 */
		flash_controller: flash-controller@4001e000 {
			compatible = "nordic,nrf52-flash-controller"; /* in zephyr\dts\arm\nordic\nrf52840.dtsi:418 */
			reg = < 0x4001e000 0x1000 >;                  /* in zephyr\dts\arm\nordic\nrf52840.dtsi:419 */
			partial-erase;                                /* in zephyr\dts\arm\nordic\nrf52840.dtsi:420 */
			#address-cells = < 0x1 >;                     /* in zephyr\dts\arm\nordic\nrf52840.dtsi:422 */
			#size-cells = < 0x1 >;                        /* in zephyr\dts\arm\nordic\nrf52840.dtsi:423 */

			/* node '/soc/flash-controller@4001e000/flash@0' defined in zephyr\dts\arm\nordic\nrf52840.dtsi:426 */
			flash0: flash@0 {
				compatible = "soc-nv-flash";   /* in zephyr\dts\arm\nordic\nrf52840.dtsi:427 */
				erase-block-size = < 0x1000 >; /* in zephyr\dts\arm\nordic\nrf52840.dtsi:428 */
				write-block-size = < 0x4 >;    /* in zephyr\dts\arm\nordic\nrf52840.dtsi:429 */
				reg = < 0x0 0x100000 >;        /* in zephyr\dts\arm\nordic\nrf52840_qiaa.dtsi:11 */

				/* node '/soc/flash-controller@4001e000/flash@0/partitions' defined in zephyr\dts\vendor\nordic\nrf52840_partition.dtsi:16 */
				partitions {
					compatible = "fixed-partitions"; /* in zephyr\dts\vendor\nordic\nrf52840_partition.dtsi:17 */
					#address-cells = < 0x1 >;        /* in zephyr\dts\vendor\nordic\nrf52840_partition.dtsi:18 */
					#size-cells = < 0x1 >;           /* in zephyr\dts\vendor\nordic\nrf52840_partition.dtsi:19 */

					/* node '/soc/flash-controller@4001e000/flash@0/partitions/partition@0' defined in zephyr\dts\vendor\nordic\nrf52840_partition.dtsi:21 */
					boot_partition: partition@0 {
						label = "mcuboot";    /* in zephyr\dts\vendor\nordic\nrf52840_partition.dtsi:22 */
						reg = < 0x0 0xc000 >; /* in zephyr\dts\vendor\nordic\nrf52840_partition.dtsi:23 */
					};

					/* node '/soc/flash-controller@4001e000/flash@0/partitions/partition@c000' defined in zephyr\dts\vendor\nordic\nrf52840_partition.dtsi:26 */
					slot0_partition: partition@c000 {
						label = "image-0";        /* in zephyr\dts\vendor\nordic\nrf52840_partition.dtsi:27 */
						reg = < 0xc000 0x76000 >; /* in zephyr\dts\vendor\nordic\nrf52840_partition.dtsi:28 */
					};

					/* node '/soc/flash-controller@4001e000/flash@0/partitions/partition@82000' defined in zephyr\dts\vendor\nordic\nrf52840_partition.dtsi:31 */
					slot1_partition: partition@82000 {
						label = "image-1";         /* in zephyr\dts\vendor\nordic\nrf52840_partition.dtsi:32 */
						reg = < 0x82000 0x76000 >; /* in zephyr\dts\vendor\nordic\nrf52840_partition.dtsi:33 */
					};

					/* node '/soc/flash-controller@4001e000/flash@0/partitions/partition@f8000' defined in zephyr\dts\vendor\nordic\nrf52840_partition.dtsi:45 */
					storage_partition: partition@f8000 {
						label = "storage";        /* in zephyr\dts\vendor\nordic\nrf52840_partition.dtsi:46 */
						reg = < 0xf8000 0x8000 >; /* in zephyr\dts\vendor\nordic\nrf52840_partition.dtsi:47 */
					};
				};
			};
		};

		/* node '/soc/ppi@4001f000' defined in zephyr\dts\arm\nordic\nrf52840.dtsi:433 */
		ppi: ppi@4001f000 {
			compatible = "nordic,nrf-ppi"; /* in zephyr\dts\arm\nordic\nrf52840.dtsi:434 */
			reg = < 0x4001f000 0x1000 >;   /* in zephyr\dts\arm\nordic\nrf52840.dtsi:435 */
			status = "okay";               /* in zephyr\dts\arm\nordic\nrf52840.dtsi:436 */
		};

		/* node '/soc/mwu@40020000' defined in zephyr\dts\arm\nordic\nrf52840.dtsi:439 */
		mwu: mwu@40020000 {
			compatible = "nordic,nrf-mwu"; /* in zephyr\dts\arm\nordic\nrf52840.dtsi:440 */
			reg = < 0x40020000 0x1000 >;   /* in zephyr\dts\arm\nordic\nrf52840.dtsi:441 */
			status = "okay";               /* in zephyr\dts\arm\nordic\nrf52840.dtsi:442 */
		};

		/* node '/soc/pwm@40021000' defined in zephyr\dts\arm\nordic\nrf52840.dtsi:445 */
		pwm1: pwm@40021000 {
			compatible = "nordic,nrf-pwm"; /* in zephyr\dts\arm\nordic\nrf52840.dtsi:446 */
			reg = < 0x40021000 0x1000 >;   /* in zephyr\dts\arm\nordic\nrf52840.dtsi:447 */
			interrupts = < 0x21 0x1 >;     /* in zephyr\dts\arm\nordic\nrf52840.dtsi:448 */
			status = "disabled";           /* in zephyr\dts\arm\nordic\nrf52840.dtsi:449 */
			#pwm-cells = < 0x3 >;          /* in zephyr\dts\arm\nordic\nrf52840.dtsi:450 */
		};

		/* node '/soc/pwm@40022000' defined in zephyr\dts\arm\nordic\nrf52840.dtsi:453 */
		pwm2: pwm@40022000 {
			compatible = "nordic,nrf-pwm"; /* in zephyr\dts\arm\nordic\nrf52840.dtsi:454 */
			reg = < 0x40022000 0x1000 >;   /* in zephyr\dts\arm\nordic\nrf52840.dtsi:455 */
			interrupts = < 0x22 0x1 >;     /* in zephyr\dts\arm\nordic\nrf52840.dtsi:456 */
			status = "disabled";           /* in zephyr\dts\arm\nordic\nrf52840.dtsi:457 */
			#pwm-cells = < 0x3 >;          /* in zephyr\dts\arm\nordic\nrf52840.dtsi:458 */
		};

		/* node '/soc/spi@40023000' defined in zephyr\dts\arm\nordic\nrf52840.dtsi:461 */
		spi2: spi@40023000 {
			compatible = "nordic,nrf-spim"; /* in zephyr\dts\arm\nordic\nrf52840.dtsi:469 */
			#address-cells = < 0x1 >;       /* in zephyr\dts\arm\nordic\nrf52840.dtsi:470 */
			#size-cells = < 0x0 >;          /* in zephyr\dts\arm\nordic\nrf52840.dtsi:471 */
			reg = < 0x40023000 0x1000 >;    /* in zephyr\dts\arm\nordic\nrf52840.dtsi:472 */
			interrupts = < 0x23 0x1 >;      /* in zephyr\dts\arm\nordic\nrf52840.dtsi:473 */
			max-frequency = < 0x7a1200 >;   /* in zephyr\dts\arm\nordic\nrf52840.dtsi:474 */
			easydma-maxcnt-bits = < 0x10 >; /* in zephyr\dts\arm\nordic\nrf52840.dtsi:475 */
			status = "disabled";            /* in zephyr\dts\arm\nordic\nrf52840.dtsi:476 */
		};

		/* node '/soc/rtc@40024000' defined in zephyr\dts\arm\nordic\nrf52840.dtsi:479 */
		rtc2: rtc@40024000 {
			compatible = "nordic,nrf-rtc"; /* in zephyr\dts\arm\nordic\nrf52840.dtsi:480 */
			reg = < 0x40024000 0x1000 >;   /* in zephyr\dts\arm\nordic\nrf52840.dtsi:481 */
			cc-num = < 0x4 >;              /* in zephyr\dts\arm\nordic\nrf52840.dtsi:482 */
			interrupts = < 0x24 0x1 >;     /* in zephyr\dts\arm\nordic\nrf52840.dtsi:483 */
			status = "disabled";           /* in zephyr\dts\arm\nordic\nrf52840.dtsi:484 */
			clock-frequency = < 0x8000 >;  /* in zephyr\dts\arm\nordic\nrf52840.dtsi:485 */
			prescaler = < 0x1 >;           /* in zephyr\dts\arm\nordic\nrf52840.dtsi:486 */
		};

		/* node '/soc/i2s@40025000' defined in zephyr\dts\arm\nordic\nrf52840.dtsi:489 */
		i2s0: i2s@40025000 {
			compatible = "nordic,nrf-i2s"; /* in zephyr\dts\arm\nordic\nrf52840.dtsi:490 */
			#address-cells = < 0x1 >;      /* in zephyr\dts\arm\nordic\nrf52840.dtsi:491 */
			#size-cells = < 0x0 >;         /* in zephyr\dts\arm\nordic\nrf52840.dtsi:492 */
			reg = < 0x40025000 0x1000 >;   /* in zephyr\dts\arm\nordic\nrf52840.dtsi:493 */
			interrupts = < 0x25 0x1 >;     /* in zephyr\dts\arm\nordic\nrf52840.dtsi:494 */
			status = "disabled";           /* in zephyr\dts\arm\nordic\nrf52840.dtsi:495 */
		};

		/* node '/soc/usbd@40027000' defined in zephyr\dts\arm\nordic\nrf52840.dtsi:498 */
		usbd: usbd@40027000 {
			compatible = "nordic,nrf-usbd"; /* in zephyr\dts\arm\nordic\nrf52840.dtsi:499 */
			reg = < 0x40027000 0x1000 >;    /* in zephyr\dts\arm\nordic\nrf52840.dtsi:500 */
			interrupts = < 0x27 0x1 >;      /* in zephyr\dts\arm\nordic\nrf52840.dtsi:501 */
			num-bidir-endpoints = < 0x1 >;  /* in zephyr\dts\arm\nordic\nrf52840.dtsi:502 */
			num-in-endpoints = < 0x7 >;     /* in zephyr\dts\arm\nordic\nrf52840.dtsi:503 */
			num-out-endpoints = < 0x7 >;    /* in zephyr\dts\arm\nordic\nrf52840.dtsi:504 */
			num-isoin-endpoints = < 0x1 >;  /* in zephyr\dts\arm\nordic\nrf52840.dtsi:505 */
			num-isoout-endpoints = < 0x1 >; /* in zephyr\dts\arm\nordic\nrf52840.dtsi:506 */
			status = "disabled";            /* in zephyr\dts\arm\nordic\nrf52840.dtsi:507 */
		};

		/* node '/soc/uart@40028000' defined in zephyr\dts\arm\nordic\nrf52840.dtsi:510 */
		uart1: uart@40028000 {
			compatible = "nordic,nrf-uarte";    /* in zephyr\dts\arm\nordic\nrf52840.dtsi:511 */
			reg = < 0x40028000 0x1000 >;        /* in zephyr\dts\arm\nordic\nrf52840.dtsi:512 */
			interrupts = < 0x28 0x1 >;          /* in zephyr\dts\arm\nordic\nrf52840.dtsi:513 */
			status = "okay";                    /* in zephyr\boards\nordic\nrf9160dk\dts\nrf52840\nrf9160dk_uart1_on_if0_3.dtsi:38 */
			pinctrl-0 = < &uart1_default_alt >; /* in pouch-gateway\controller\boards\nrf9160dk_nrf52840.overlay:39 */
			pinctrl-1 = < &uart1_sleep_alt >;   /* in pouch-gateway\controller\boards\nrf9160dk_nrf52840.overlay:40 */
			pinctrl-names = "default",
			                "sleep";            /* in pouch-gateway\controller\boards\nrf9160dk_nrf52840.overlay:41 */
			current-speed = < 0xf4240 >;        /* in pouch-gateway\controller\boards\nrf9160dk_nrf52840.overlay:38 */

			/* node '/soc/uart@40028000/nrf-sw-lpuart' defined in pouch-gateway\controller\boards\nrf9160dk_nrf52840.overlay:43 */
			lpuart: nrf-sw-lpuart {
				compatible = "nordic,nrf-sw-lpuart"; /* in pouch-gateway\controller\boards\nrf9160dk_nrf52840.overlay:44 */
				status = "okay";                     /* in pouch-gateway\controller\boards\nrf9160dk_nrf52840.overlay:45 */
				req-pin = < 0xf >;                   /* in pouch-gateway\controller\boards\nrf9160dk_nrf52840.overlay:46 */
				rdy-pin = < 0x16 >;                  /* in pouch-gateway\controller\boards\nrf9160dk_nrf52840.overlay:47 */
			};
		};

		/* node '/soc/qspi@40029000' defined in zephyr\dts\arm\nordic\nrf52840.dtsi:517 */
		qspi: qspi@40029000 {
			compatible = "nordic,nrf-qspi"; /* in zephyr\dts\arm\nordic\nrf52840.dtsi:518 */
			#address-cells = < 0x1 >;       /* in zephyr\dts\arm\nordic\nrf52840.dtsi:519 */
			#size-cells = < 0x0 >;          /* in zephyr\dts\arm\nordic\nrf52840.dtsi:520 */
			reg = < 0x40029000 0x1000 >,
			      < 0x12000000 0x8000000 >; /* in zephyr\dts\arm\nordic\nrf52840.dtsi:521 */
			reg-names = "qspi",
			            "qspi_mm";          /* in zephyr\dts\arm\nordic\nrf52840.dtsi:522 */
			interrupts = < 0x29 0x1 >;      /* in zephyr\dts\arm\nordic\nrf52840.dtsi:523 */
			status = "disabled";            /* in zephyr\dts\arm\nordic\nrf52840.dtsi:524 */
		};

		/* node '/soc/pwm@4002d000' defined in zephyr\dts\arm\nordic\nrf52840.dtsi:527 */
		pwm3: pwm@4002d000 {
			compatible = "nordic,nrf-pwm"; /* in zephyr\dts\arm\nordic\nrf52840.dtsi:528 */
			reg = < 0x4002d000 0x1000 >;   /* in zephyr\dts\arm\nordic\nrf52840.dtsi:529 */
			interrupts = < 0x2d 0x1 >;     /* in zephyr\dts\arm\nordic\nrf52840.dtsi:530 */
			status = "disabled";           /* in zephyr\dts\arm\nordic\nrf52840.dtsi:531 */
			#pwm-cells = < 0x3 >;          /* in zephyr\dts\arm\nordic\nrf52840.dtsi:532 */
		};

		/* node '/soc/spi@4002f000' defined in zephyr\dts\arm\nordic\nrf52840.dtsi:535 */
		spi3: spi@4002f000 {
			compatible = "nordic,nrf-spim"; /* in zephyr\dts\arm\nordic\nrf52840.dtsi:536 */
			#address-cells = < 0x1 >;       /* in zephyr\dts\arm\nordic\nrf52840.dtsi:537 */
			#size-cells = < 0x0 >;          /* in zephyr\dts\arm\nordic\nrf52840.dtsi:538 */
			reg = < 0x4002f000 0x1000 >;    /* in zephyr\dts\arm\nordic\nrf52840.dtsi:539 */
			interrupts = < 0x2f 0x1 >;      /* in zephyr\dts\arm\nordic\nrf52840.dtsi:540 */
			max-frequency = < 0x1e84800 >;  /* in zephyr\dts\arm\nordic\nrf52840.dtsi:541 */
			easydma-maxcnt-bits = < 0x10 >; /* in zephyr\dts\arm\nordic\nrf52840.dtsi:542 */
			rx-delay-supported;             /* in zephyr\dts\arm\nordic\nrf52840.dtsi:543 */
			rx-delay = < 0x2 >;             /* in zephyr\dts\arm\nordic\nrf52840.dtsi:544 */
			status = "disabled";            /* in zephyr\dts\arm\nordic\nrf52840.dtsi:545 */
		};

		/* node '/soc/gpio@50000000' defined in zephyr\dts\arm\nordic\nrf52840.dtsi:548 */
		gpio0: gpio@50000000 {
			compatible = "nordic,nrf-gpio";              /* in zephyr\dts\arm\nordic\nrf52840.dtsi:549 */
			gpio-controller;                             /* in zephyr\dts\arm\nordic\nrf52840.dtsi:550 */
			reg = < 0x50000000 0x200 0x50000500 0x300 >; /* in zephyr\dts\arm\nordic\nrf52840.dtsi:551 */
			#gpio-cells = < 0x2 >;                       /* in zephyr\dts\arm\nordic\nrf52840.dtsi:553 */
			status = "okay";                             /* in zephyr\boards\nordic\nrf9160dk\nrf9160dk_nrf52840.dts:155 */
			port = < 0x0 >;                              /* in zephyr\dts\arm\nordic\nrf52840.dtsi:555 */
			gpiote-instance = < &gpiote >;               /* in zephyr\dts\arm\nordic\nrf52840.dtsi:556 */
			phandle = < 0x8 >;                           /* in zephyr\boards\nordic\nrf9160dk\nrf9160dk_nrf52840_0_14_0.overlay:30 */
		};

		/* node '/soc/gpio@50000300' defined in zephyr\dts\arm\nordic\nrf52840.dtsi:559 */
		gpio1: gpio@50000300 {
			compatible = "nordic,nrf-gpio";              /* in zephyr\dts\arm\nordic\nrf52840.dtsi:560 */
			gpio-controller;                             /* in zephyr\dts\arm\nordic\nrf52840.dtsi:561 */
			reg = < 0x50000300 0x200 0x50000800 0x300 >; /* in zephyr\dts\arm\nordic\nrf52840.dtsi:562 */
			#gpio-cells = < 0x2 >;                       /* in zephyr\dts\arm\nordic\nrf52840.dtsi:564 */
			ngpios = < 0x10 >;                           /* in zephyr\dts\arm\nordic\nrf52840.dtsi:565 */
			status = "okay";                             /* in zephyr\boards\nordic\nrf9160dk\nrf9160dk_nrf52840.dts:159 */
			port = < 0x1 >;                              /* in zephyr\dts\arm\nordic\nrf52840.dtsi:567 */
			gpiote-instance = < &gpiote >;               /* in zephyr\dts\arm\nordic\nrf52840.dtsi:568 */
			phandle = < 0x9 >;                           /* in zephyr\boards\nordic\nrf9160dk\nrf9160dk_nrf52840_0_14_0.overlay:30 */
		};

		/* node '/soc/crypto@5002a000' defined in zephyr\dts\arm\nordic\nrf52840.dtsi:571 */
		cryptocell: crypto@5002a000 {
			compatible = "arm,cryptocell-310"; /* in zephyr\dts\arm\nordic\nrf52840.dtsi:572 */
			reg = < 0x5002a000 0x1000 >,
			      < 0x5002b000 0x1000 >;       /* in zephyr\dts\arm\nordic\nrf52840.dtsi:573 */
			reg-names = "wrapper",
			            "core";                /* in zephyr\dts\arm\nordic\nrf52840.dtsi:574 */
			interrupts = < 0x2a 0x1 >;         /* in zephyr\dts\arm\nordic\nrf52840.dtsi:575 */
			status = "okay";                   /* in zephyr\dts\arm\nordic\nrf52840.dtsi:576 */
		};
	};

	/* node '/pin-controller' defined in zephyr\dts\vendor\nordic\nrf_common.dtsi:25 */
	pinctrl: pin-controller {
		compatible = "nordic,nrf-pinctrl"; /* in zephyr\dts\vendor\nordic\nrf_common.dtsi:30 */

		/* node '/pin-controller/uart0_default' defined in zephyr\boards\nordic\nrf9160dk\nrf9160dk_nrf52840-pinctrl.dtsi:7 */
		uart0_default: uart0_default {

			/* node '/pin-controller/uart0_default/group1' defined in zephyr\boards\nordic\nrf9160dk\nrf9160dk_nrf52840-pinctrl.dtsi:8 */
			group1 {
				psels = < 0x5 >,
				        < 0x2000007 >; /* in zephyr\boards\nordic\nrf9160dk\nrf9160dk_nrf52840-pinctrl.dtsi:9 */
			};

			/* node '/pin-controller/uart0_default/group2' defined in zephyr\boards\nordic\nrf9160dk\nrf9160dk_nrf52840-pinctrl.dtsi:13 */
			group2 {
				psels = < 0x1000003 >,
				        < 0x3000028 >; /* in zephyr\boards\nordic\nrf9160dk\nrf9160dk_nrf52840-pinctrl.dtsi:14 */
				bias-pull-up;          /* in zephyr\boards\nordic\nrf9160dk\nrf9160dk_nrf52840-pinctrl.dtsi:16 */
			};
		};

		/* node '/pin-controller/uart0_sleep' defined in zephyr\boards\nordic\nrf9160dk\nrf9160dk_nrf52840-pinctrl.dtsi:20 */
		uart0_sleep: uart0_sleep {

			/* node '/pin-controller/uart0_sleep/group1' defined in zephyr\boards\nordic\nrf9160dk\nrf9160dk_nrf52840-pinctrl.dtsi:21 */
			group1 {
				psels = < 0x5 >,
				        < 0x1000003 >,
				        < 0x2000007 >,
				        < 0x3000028 >; /* in zephyr\boards\nordic\nrf9160dk\nrf9160dk_nrf52840-pinctrl.dtsi:22 */
				low-power-enable;      /* in zephyr\boards\nordic\nrf9160dk\nrf9160dk_nrf52840-pinctrl.dtsi:26 */
			};
		};

		/* node '/pin-controller/uart1_default_alt' defined in zephyr\boards\nordic\nrf9160dk\dts\nrf52840\nrf9160dk_uart1_on_if0_3.dtsi:16 */
		uart1_default_alt: uart1_default_alt {
			phandle = < 0x4 >; /* in pouch-gateway\controller\boards\nrf9160dk_nrf52840.overlay:39 */

			/* node '/pin-controller/uart1_default_alt/group1' defined in zephyr\boards\nordic\nrf9160dk\dts\nrf52840\nrf9160dk_uart1_on_if0_3.dtsi:17 */
			group1 {
				psels = < 0x11 >,
				        < 0x1000014 >; /* in pouch-gateway\controller\boards\nrf9160dk_nrf52840.overlay:22 */
			};
		};

		/* node '/pin-controller/uart1_sleep_alt' defined in zephyr\boards\nordic\nrf9160dk\dts\nrf52840\nrf9160dk_uart1_on_if0_3.dtsi:25 */
		uart1_sleep_alt: uart1_sleep_alt {
			phandle = < 0x5 >; /* in pouch-gateway\controller\boards\nrf9160dk_nrf52840.overlay:40 */

			/* node '/pin-controller/uart1_sleep_alt/group1' defined in zephyr\boards\nordic\nrf9160dk\dts\nrf52840\nrf9160dk_uart1_on_if0_3.dtsi:26 */
			group1 {
				psels = < 0x11 >,
				        < 0x1000014 >; /* in pouch-gateway\controller\boards\nrf9160dk_nrf52840.overlay:29 */
				low-power-enable;      /* in pouch-gateway\controller\boards\nrf9160dk_nrf52840.overlay:31 */
			};
		};

		/* node '/pin-controller/uart0_default_alt' defined in pouch-gateway\controller\boards\nrf9160dk_nrf52840.overlay:7 */
		uart0_default_alt: uart0_default_alt {
			phandle = < 0x2 >; /* in pouch-gateway\controller\boards\nrf9160dk_nrf52840.overlay:63 */

			/* node '/pin-controller/uart0_default_alt/group1' defined in pouch-gateway\controller\boards\nrf9160dk_nrf52840.overlay:8 */
			group1 {
				psels = < 0x5 >; /* in pouch-gateway\controller\boards\nrf9160dk_nrf52840.overlay:9 */
			};
		};

		/* node '/pin-controller/uart0_sleep_alt' defined in pouch-gateway\controller\boards\nrf9160dk_nrf52840.overlay:13 */
		uart0_sleep_alt: uart0_sleep_alt {
			phandle = < 0x3 >; /* in pouch-gateway\controller\boards\nrf9160dk_nrf52840.overlay:64 */

			/* node '/pin-controller/uart0_sleep_alt/group1' defined in pouch-gateway\controller\boards\nrf9160dk_nrf52840.overlay:14 */
			group1 {
				psels = < 0x5 >;  /* in pouch-gateway\controller\boards\nrf9160dk_nrf52840.overlay:15 */
				low-power-enable; /* in pouch-gateway\controller\boards\nrf9160dk_nrf52840.overlay:16 */
			};
		};
	};

	/* node '/entropy_bt_hci' defined in zephyr\dts\vendor\nordic\nrf_common.dtsi:33 */
	rng_hci: entropy_bt_hci {
		compatible = "zephyr,bt-hci-entropy"; /* in zephyr\dts\vendor\nordic\nrf_common.dtsi:34 */
		status = "okay";                      /* in zephyr\dts\vendor\nordic\nrf_common.dtsi:35 */
	};

	/* node '/sw-pwm' defined in zephyr\dts\vendor\nordic\nrf_common.dtsi:38 */
	sw_pwm: sw-pwm {
		compatible = "nordic,nrf-sw-pwm"; /* in zephyr\dts\vendor\nordic\nrf_common.dtsi:39 */
		status = "disabled";              /* in zephyr\dts\vendor\nordic\nrf_common.dtsi:40 */
		generator = < &timer1 >;          /* in zephyr\dts\vendor\nordic\nrf_common.dtsi:41 */
		clock-prescaler = < 0x0 >;        /* in zephyr\dts\vendor\nordic\nrf_common.dtsi:42 */
		#pwm-cells = < 0x3 >;             /* in zephyr\dts\vendor\nordic\nrf_common.dtsi:43 */
	};

	/* node '/cpus' defined in zephyr\dts\arm\nordic\nrf52840.dtsi:15 */
	cpus {
		#address-cells = < 0x1 >; /* in zephyr\dts\arm\nordic\nrf52840.dtsi:16 */
		#size-cells = < 0x0 >;    /* in zephyr\dts\arm\nordic\nrf52840.dtsi:17 */

		/* node '/cpus/cpu@0' defined in zephyr\dts\arm\nordic\nrf52840.dtsi:19 */
		cpu@0 {
			device_type = "cpu";           /* in zephyr\dts\arm\nordic\nrf52840.dtsi:20 */
			compatible = "arm,cortex-m4f"; /* in zephyr\dts\arm\nordic\nrf52840.dtsi:21 */
			reg = < 0x0 >;                 /* in zephyr\dts\arm\nordic\nrf52840.dtsi:22 */
			#address-cells = < 0x1 >;      /* in zephyr\dts\arm\nordic\nrf52840.dtsi:23 */
			#size-cells = < 0x1 >;         /* in zephyr\dts\arm\nordic\nrf52840.dtsi:24 */

			/* node '/cpus/cpu@0/itm@e0000000' defined in zephyr\dts\arm\nordic\nrf52840.dtsi:26 */
			itm: itm@e0000000 {
				compatible = "arm,armv7m-itm";     /* in zephyr\dts\arm\nordic\nrf52840.dtsi:27 */
				reg = < 0xe0000000 0x1000 >;       /* in zephyr\dts\arm\nordic\nrf52840.dtsi:28 */
				swo-ref-frequency = < 0x1e84800 >; /* in zephyr\dts\arm\nordic\nrf52840.dtsi:29 */
			};
		};
	};

	/* node '/clocks' defined in zephyr\dts\arm\nordic\nrf52840.dtsi:34 */
	clocks {

		/* node '/clocks/hfxo' defined in zephyr\dts\arm\nordic\nrf52840.dtsi:35 */
		hfxo: hfxo {
			compatible = "nordic,nrf52-hfxo"; /* in zephyr\dts\arm\nordic\nrf52840.dtsi:36 */
			clock-frequency = < 0x3d09000 >;  /* in zephyr\dts\arm\nordic\nrf52840.dtsi:37 */
			startup-time-us = < 0x578 >;      /* in zephyr\dts\arm\nordic\nrf52840.dtsi:38 */
			#clock-cells = < 0x0 >;           /* in zephyr\dts\arm\nordic\nrf52840.dtsi:39 */
		};
	};

	/* node '/gpio-interface' defined in zephyr\boards\nordic\nrf9160dk\nrf9160dk_nrf52840.dts:25 */
	interface_to_nrf9160: gpio-interface {
		compatible = "nordic,nrf9160dk-nrf52840-interface"; /* in zephyr\boards\nordic\nrf9160dk\nrf9160dk_nrf52840.dts:26 */
		#gpio-cells = < 0x2 >;                              /* in zephyr\boards\nordic\nrf9160dk\nrf9160dk_nrf52840.dts:27 */
		gpio-map-mask = < 0xf 0x0 >;                        /* in zephyr\boards\nordic\nrf9160dk\nrf9160dk_nrf52840.dts:28 */
		gpio-map-pass-thru = < 0x0 0xffffffff >;            /* in zephyr\boards\nordic\nrf9160dk\nrf9160dk_nrf52840.dts:29 */
		gpio-map = < 0x0 0x0 &gpio0 0x11 0x0 >,
		           < 0x1 0x0 &gpio0 0x14 0x0 >,
		           < 0x2 0x0 &gpio0 0xf 0x0 >,
		           < 0x3 0x0 &gpio0 0x16 0x0 >,
		           < 0x4 0x0 &gpio1 0x4 0x0 >,
		           < 0x5 0x0 &gpio1 0x2 0x0 >,
		           < 0x6 0x0 &gpio1 0xd 0x0 >,
		           < 0x7 0x0 &gpio1 0xb 0x0 >,
		           < 0x8 0x0 &gpio1 0xf 0x0 >,
		           < 0x9 0x0 &gpio0 0x12 0x0 >;             /* in zephyr\boards\nordic\nrf9160dk\nrf9160dk_nrf52840_0_14_0.overlay:30 */
		phandle = < 0xa >;                                  /* in zephyr\boards\nordic\nrf9160dk\dts\nrf52840\nrf9160dk_nrf52840_reset_on_if9.dtsi:15 */
	};

	/* node '/gpio-reset' defined in zephyr\boards\nordic\nrf9160dk\nrf9160dk_nrf52840.dts:41 */
	reset_input: gpio-reset {
		compatible = "nordic,nrf9160dk-nrf52840-reset"; /* in zephyr\boards\nordic\nrf9160dk\nrf9160dk_nrf52840.dts:42 */
		gpios = < &interface_to_nrf9160 0x9 0x11 >;     /* in zephyr\boards\nordic\nrf9160dk\dts\nrf52840\nrf9160dk_nrf52840_reset_on_if9.dtsi:15 */
		status = "okay";                                /* in zephyr\boards\nordic\nrf9160dk\dts\nrf52840\nrf9160dk_nrf52840_reset_on_if9.dtsi:14 */
	};

	/* node '/board-control' defined in zephyr\boards\nordic\nrf9160dk\nrf9160dk_nrf52840.dts:52 */
	board-control {

		/* node '/board-control/switch-nrf91-uart1' defined in zephyr\boards\nordic\nrf9160dk\nrf9160dk_nrf52840.dts:53 */
		vcom0_pins_routing: switch-nrf91-uart1 {
			compatible = "nordic,nrf9160dk-optional-routing"; /* in zephyr\boards\nordic\nrf9160dk\nrf9160dk_nrf52840.dts:54 */
			control-gpios = < &gpio1 0xe 0x1 >;               /* in zephyr\boards\nordic\nrf9160dk\nrf9160dk_nrf52840.dts:55 */
			status = "okay";                                  /* in zephyr\boards\nordic\nrf9160dk\nrf9160dk_nrf52840.dts:56 */
		};

		/* node '/board-control/switch-nrf91-uart2' defined in zephyr\boards\nordic\nrf9160dk\nrf9160dk_nrf52840.dts:59 */
		vcom2_pins_routing: switch-nrf91-uart2 {
			compatible = "nordic,nrf9160dk-optional-routing"; /* in zephyr\boards\nordic\nrf9160dk\nrf9160dk_nrf52840.dts:60 */
			control-gpios = < &gpio1 0xc 0x0 >;               /* in zephyr\boards\nordic\nrf9160dk\nrf9160dk_nrf52840_0_14_0.overlay:45 */
			status = "okay";                                  /* in zephyr\boards\nordic\nrf9160dk\nrf9160dk_nrf52840.dts:67 */
		};

		/* node '/board-control/switch-nrf91-led1' defined in zephyr\boards\nordic\nrf9160dk\nrf9160dk_nrf52840.dts:70 */
		led1_pin_routing: switch-nrf91-led1 {
			compatible = "nordic,nrf9160dk-optional-routing"; /* in zephyr\boards\nordic\nrf9160dk\nrf9160dk_nrf52840.dts:71 */
			control-gpios = < &gpio1 0x5 0x1 >;               /* in zephyr\boards\nordic\nrf9160dk\nrf9160dk_nrf52840.dts:72 */
			status = "okay";                                  /* in zephyr\boards\nordic\nrf9160dk\nrf9160dk_nrf52840.dts:73 */
		};

		/* node '/board-control/switch-nrf91-led2' defined in zephyr\boards\nordic\nrf9160dk\nrf9160dk_nrf52840.dts:76 */
		led2_pin_routing: switch-nrf91-led2 {
			compatible = "nordic,nrf9160dk-optional-routing"; /* in zephyr\boards\nordic\nrf9160dk\nrf9160dk_nrf52840.dts:77 */
			control-gpios = < &gpio1 0x7 0x1 >;               /* in zephyr\boards\nordic\nrf9160dk\nrf9160dk_nrf52840.dts:78 */
			status = "okay";                                  /* in zephyr\boards\nordic\nrf9160dk\nrf9160dk_nrf52840.dts:79 */
		};

		/* node '/board-control/switch-nrf91-led3' defined in zephyr\boards\nordic\nrf9160dk\nrf9160dk_nrf52840.dts:82 */
		led3_pin_routing: switch-nrf91-led3 {
			compatible = "nordic,nrf9160dk-optional-routing"; /* in zephyr\boards\nordic\nrf9160dk\nrf9160dk_nrf52840.dts:83 */
			control-gpios = < &gpio1 0x1 0x1 >;               /* in zephyr\boards\nordic\nrf9160dk\nrf9160dk_nrf52840.dts:84 */
			status = "okay";                                  /* in zephyr\boards\nordic\nrf9160dk\nrf9160dk_nrf52840.dts:85 */
		};

		/* node '/board-control/switch-nrf91-led4' defined in zephyr\boards\nordic\nrf9160dk\nrf9160dk_nrf52840.dts:88 */
		led4_pin_routing: switch-nrf91-led4 {
			compatible = "nordic,nrf9160dk-optional-routing"; /* in zephyr\boards\nordic\nrf9160dk\nrf9160dk_nrf52840.dts:89 */
			control-gpios = < &gpio1 0x3 0x1 >;               /* in zephyr\boards\nordic\nrf9160dk\nrf9160dk_nrf52840.dts:90 */
			status = "okay";                                  /* in zephyr\boards\nordic\nrf9160dk\nrf9160dk_nrf52840.dts:91 */
		};

		/* node '/board-control/switch-nrf91-switch1' defined in zephyr\boards\nordic\nrf9160dk\nrf9160dk_nrf52840.dts:94 */
		switch1_pin_routing: switch-nrf91-switch1 {
			compatible = "nordic,nrf9160dk-optional-routing"; /* in zephyr\boards\nordic\nrf9160dk\nrf9160dk_nrf52840.dts:95 */
			control-gpios = < &gpio1 0x9 0x1 >;               /* in zephyr\boards\nordic\nrf9160dk\nrf9160dk_nrf52840.dts:96 */
			status = "okay";                                  /* in zephyr\boards\nordic\nrf9160dk\nrf9160dk_nrf52840.dts:97 */
		};

		/* node '/board-control/switch-nrf91-switch2' defined in zephyr\boards\nordic\nrf9160dk\nrf9160dk_nrf52840.dts:100 */
		switch2_pin_routing: switch-nrf91-switch2 {
			compatible = "nordic,nrf9160dk-optional-routing"; /* in zephyr\boards\nordic\nrf9160dk\nrf9160dk_nrf52840.dts:101 */
			control-gpios = < &gpio0 0x8 0x1 >;               /* in zephyr\boards\nordic\nrf9160dk\nrf9160dk_nrf52840.dts:102 */
			status = "okay";                                  /* in zephyr\boards\nordic\nrf9160dk\nrf9160dk_nrf52840.dts:103 */
		};

		/* node '/board-control/switch-nrf91-button1' defined in zephyr\boards\nordic\nrf9160dk\nrf9160dk_nrf52840.dts:106 */
		button1_pin_routing: switch-nrf91-button1 {
			compatible = "nordic,nrf9160dk-optional-routing"; /* in zephyr\boards\nordic\nrf9160dk\nrf9160dk_nrf52840.dts:107 */
			control-gpios = < &gpio0 0x6 0x1 >;               /* in zephyr\boards\nordic\nrf9160dk\nrf9160dk_nrf52840.dts:108 */
			status = "okay";                                  /* in zephyr\boards\nordic\nrf9160dk\nrf9160dk_nrf52840.dts:109 */
		};

		/* node '/board-control/switch-nrf91-button2' defined in zephyr\boards\nordic\nrf9160dk\nrf9160dk_nrf52840.dts:112 */
		button2_pin_routing: switch-nrf91-button2 {
			compatible = "nordic,nrf9160dk-optional-routing"; /* in zephyr\boards\nordic\nrf9160dk\nrf9160dk_nrf52840.dts:113 */
			control-gpios = < &gpio0 0x1a 0x1 >;              /* in zephyr\boards\nordic\nrf9160dk\nrf9160dk_nrf52840.dts:114 */
			status = "okay";                                  /* in zephyr\boards\nordic\nrf9160dk\nrf9160dk_nrf52840.dts:115 */
		};

		/* node '/board-control/switch-nrf-if0-2-ctrl' defined in zephyr\boards\nordic\nrf9160dk\nrf9160dk_nrf52840.dts:118 */
		nrf_interface_pins_0_2_routing: switch-nrf-if0-2-ctrl {
			compatible = "nordic,nrf9160dk-optional-routing"; /* in zephyr\boards\nordic\nrf9160dk\nrf9160dk_nrf52840.dts:119 */
			control-gpios = < &gpio0 0xd 0x0 >;               /* in zephyr\boards\nordic\nrf9160dk\nrf9160dk_nrf52840.dts:120 */
			status = "okay";                                  /* in zephyr\boards\nordic\nrf9160dk\dts\nrf52840\nrf9160dk_uart1_on_if0_3.dtsi:8 */
		};

		/* node '/board-control/switch-nrf-if3-5-ctrl' defined in zephyr\boards\nordic\nrf9160dk\nrf9160dk_nrf52840.dts:124 */
		nrf_interface_pins_3_5_routing: switch-nrf-if3-5-ctrl {
			compatible = "nordic,nrf9160dk-optional-routing"; /* in zephyr\boards\nordic\nrf9160dk\nrf9160dk_nrf52840.dts:125 */
			control-gpios = < &gpio0 0x18 0x0 >;              /* in zephyr\boards\nordic\nrf9160dk\nrf9160dk_nrf52840.dts:126 */
			status = "okay";                                  /* in zephyr\boards\nordic\nrf9160dk\dts\nrf52840\nrf9160dk_uart1_on_if0_3.dtsi:12 */
		};

		/* node '/board-control/switch-nrf-if6-8-ctrl' defined in zephyr\boards\nordic\nrf9160dk\nrf9160dk_nrf52840.dts:130 */
		nrf_interface_pins_6_8_routing: switch-nrf-if6-8-ctrl {
			compatible = "nordic,nrf9160dk-optional-routing"; /* in zephyr\boards\nordic\nrf9160dk\nrf9160dk_nrf52840.dts:131 */
			control-gpios = < &gpio1 0xa 0x0 >;               /* in zephyr\boards\nordic\nrf9160dk\nrf9160dk_nrf52840.dts:132 */
			status = "disabled";                              /* in zephyr\boards\nordic\nrf9160dk\nrf9160dk_nrf52840.dts:133 */
		};

		/* node '/board-control/switch-nrf-if9-ctrl' defined in zephyr\boards\nordic\nrf9160dk\nrf9160dk_nrf52840_0_14_0.overlay:9 */
		nrf_interface_pin_9_routing: switch-nrf-if9-ctrl {
			compatible = "nordic,nrf9160dk-optional-routing"; /* in zephyr\boards\nordic\nrf9160dk\nrf9160dk_nrf52840_0_14_0.overlay:10 */
			control-gpios = < &gpio0 0x10 0x0 >;              /* in zephyr\boards\nordic\nrf9160dk\nrf9160dk_nrf52840_0_14_0.overlay:11 */
			status = "okay";                                  /* in zephyr\boards\nordic\nrf9160dk\dts\nrf52840\nrf9160dk_nrf52840_reset_on_if9.dtsi:10 */
		};

		/* node '/board-control/switch-io-exp-en' defined in zephyr\boards\nordic\nrf9160dk\nrf9160dk_nrf52840_0_14_0.overlay:15 */
		io_expander_pins_routing: switch-io-exp-en {
			compatible = "nordic,nrf9160dk-optional-routing"; /* in zephyr\boards\nordic\nrf9160dk\nrf9160dk_nrf52840_0_14_0.overlay:16 */
			control-gpios = < &gpio0 0xe 0x0 >;               /* in zephyr\boards\nordic\nrf9160dk\nrf9160dk_nrf52840_0_14_0.overlay:17 */
			status = "disabled";                              /* in zephyr\boards\nordic\nrf9160dk\nrf9160dk_nrf52840_0_14_0.overlay:18 */
		};

		/* node '/board-control/switch-ext-mem-ctrl' defined in zephyr\boards\nordic\nrf9160dk\nrf9160dk_nrf52840_0_14_0.overlay:21 */
		external_flash_pins_routing: switch-ext-mem-ctrl {
			compatible = "nordic,nrf9160dk-optional-routing"; /* in zephyr\boards\nordic\nrf9160dk\nrf9160dk_nrf52840_0_14_0.overlay:22 */
			control-gpios = < &gpio0 0x13 0x0 >;              /* in zephyr\boards\nordic\nrf9160dk\nrf9160dk_nrf52840_0_14_0.overlay:23 */
			status = "okay";                                  /* in zephyr\boards\nordic\nrf9160dk\nrf9160dk_nrf52840_0_14_0.overlay:24 */
		};
	};
};
